# ptg_reva2_8pt register map
Registers are 32-bit, read-write, no defined reset value unless marked. A register's access mark holds for its fields unless they carry their own. Offsets are from the block's base; lines under a group give offsets from that group; [hi:lo] are bit positions; {n}, {i} and the like mark numbered series; 'fields as' and 'values as' point back to an identical list; <NAME> marks a mode.

## Memory map
0x4003C000 PTG size 0x20 — Pulse Train Generation

## Interrupts
59 PT (PTG) — Pulse Train IRQ

## PTG — Pulse Train Generation
Base 0x4003C000
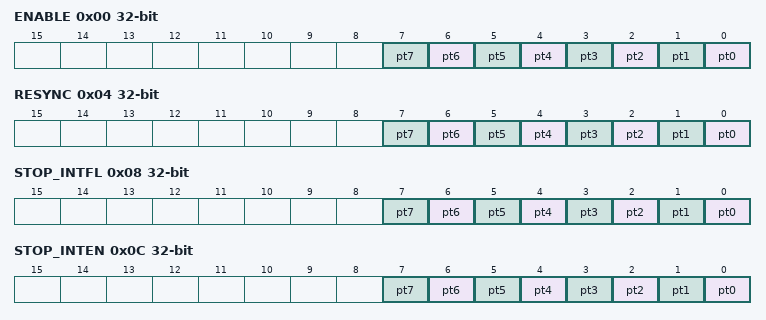
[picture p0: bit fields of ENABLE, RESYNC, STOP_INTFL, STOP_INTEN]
0x00 ENABLE — Global Enable/Disable Controls for All Pulse Trains
  [n] pt{n} (n=0..7) — Enable/Disable control for PT{n}
0x04 RESYNC — Global Resync (All Pulse Trains) Control
  [n] pt{n} (n=0..7) — Resync control for PT{n}
0x08 STOP_INTFL — Pulse Train Stop Interrupt Flags
  [n] pt{n} (n=0..7) — Pulse Train {n} Stopped Interrupt Flag
0x0C STOP_INTEN — Pulse Train Stop Interrupt Enable/Disable
  [n] pt{n} (n=0..7) — Pulse Train {n} Stopped Interrupt Enable/Disable
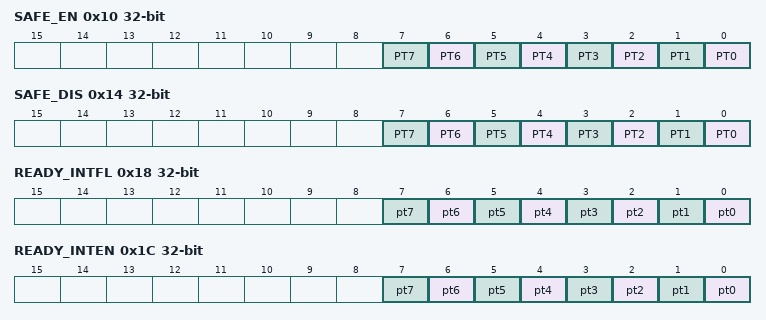
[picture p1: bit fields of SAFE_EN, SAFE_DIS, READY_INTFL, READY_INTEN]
0x10 SAFE_EN wo — Pulse Train Global Safe Enable.
  [n] PT{n} (n=0..7)
0x14 SAFE_DIS wo — Pulse Train Global Safe Disable.
  [n] PT{n} (n=0..7)
0x18 READY_INTFL — Pulse Train Ready Interrupt Flags
  [n] pt{n} (n=0..7) — Pulse Train {n} Ready Interrupt Flag
0x1C READY_INTEN — Pulse Train Ready Interrupt Enable/Disable
  [n] pt{n} (n=0..7) — Pulse Train {n} Ready Interrupt Enable/Disable
